# tviic2d6mddr register map
Vendor: Cypress Semiconductor; Series: tviic2d6mddr; File version: 1.0
CPU: CM7 r0p1, little endian, MPU, FPU, VTOR, 3 interrupt priority bits
Registers are 32-bit, read-write, reset 0x0 unless marked. A register's access mark holds for its fields unless they carry their own. Offsets are from the block's base; [hi:lo] are bit positions; lines under a group give offsets from that group; {n}, {i} and the like mark numbered series; 'fields as' and 'values as' point back to an identical list.

## TCPWM0 — Timer/Counter/PWM
Base 0x40380000
{0x0+0x8000*i} GRP[{i}] (i=0..2) group — Group of counters
  {0x0+0x80*j} CNT[{j}] (j=0..37) group — Timer/Counter/PWM Counter Module
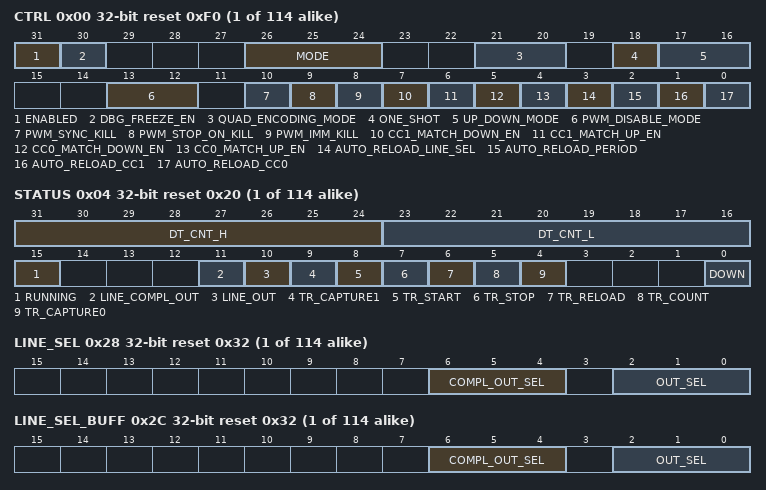
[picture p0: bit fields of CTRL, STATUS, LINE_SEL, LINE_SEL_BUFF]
    0x00 CTRL reset 0xF0 — Counter control register
      [31] ENABLED — Counter Enable '0': counter disabled. '1': counter enabled. Counter static configuration register fields should only be modified when the counter is disabled. When a counter is disabled, command and status information associated to the counter is cleared by HW, this includes: - the associated counter triggers in the CMD register are set to '0'. - the counter's interrupt cause fields in counter's INTR register. - the counter's status fields in counter's STATUS register.. - the counter's trigger outputs ('tr_out0' and tr_out1'). - the counter's line outputs ('line_out' and 'line_compl_out'). The following are Counter static configuration registers: CTRL (with the exception of DEBUG_FREEZE_EN bit), DT, TR_IN_SEL0, TR_IN_SEL1, TR_IN_EDGE_SEL, TR_PWM_CTRL_TR_OUT_SEL,INTR, INTR_MASK, INTR_MASKED Modifying these registers while the counter is running could produce unexcepted waveform results, but will not cause a fatal issue such as an illegal stop, lost control, or waveform stability issues.
      [30] DBG_FREEZE_EN — Specifies the counter behavior in debug mode. '0': The counter operation continues in debug mode. '1': The counter operation freezes in debug mode.
      [26:24] MODE — Counter mode.
        0=TIMER (Timer mode); 1=RSVD1 (N/A); 2=CAPTURE (Capture mode); 3=QUAD (Quadrature mode Different encoding modes can be selected by QUAD_ENCODING_MODE including up/down count functionality. Different counter range, reload value and capture behavior can be selected by QUAD_RANGE_MODE (overloaded field UP_DOWN_MODE).); 4=PWM (Pulse width modulation (PWM) mode); 5=PWM_DT (PWM with deadtime insertion mode); 6=PWM_PR (Pseudo random pulse width modulation); 7=SR (Shift register mode.)
      [21:20] QUAD_ENCODING_MODE — In QUAD mode this field selects the quadrature encoding mode (X1/X2/X4) or the Up / Down rotary counting mode. In PWM, PWM_DT and PWM_PR modes, these two bits can be used to invert 'dt_line_out' and 'dt_line_compl_out'. Inversion is the last step in generation of 'dt_line_out' and 'dt_line_compl_out'; i.e. a disabled output line 'dt_line_out' has the value QUAD_ENCODING_MODE[0] and a disabled output line 'dt_line_compl_out' has the value QUAD_ENCODING_MODE[1].
        0=X1 encoding (QUAD mode) This encoding is identical with an up / down counting functionality of the following way: Rising edges of input phiA increment or decrement the counter depending on the state of input phiB (direction input); 1=X2 (X2 encoding (QUAD mode)); 2=X4 (X4 encoding (QUAD mode)); 3=UP_DOWN (Up / Down rotary counting mode. Input phiA increments the counter, input phiB decrements the counter. The trigger edge detection settings apply.)
      [18] ONE_SHOT — When '0', counter runs continuous. When '1', counter is turned off by hardware when a terminal count event is generated.
      [17:16] UP_DOWN_MODE — Determines counter direction. In QUAD mode this field acts as QUAD_RANGE_MODE field selecting between different counter range, reload value and compare / capture behavior.
        0=COUNT_UP (Count up (to PERIOD). An overflow event is generated when the counter changes from a state in which COUNTER equals PERIOD. A terminal count event is generated when the counter changes from a state in which COUNTER equals PERIOD.); 1=COUNT_DOWN (Count down (to '0'). An underflow event is generated when the counter changes from a state in which COUNTER equals '0'. A terminal count event is generated when the counter changes from a state in which COUNTER equals '0'.); 2=COUNT_UPDN1 (Count up (to PERIOD), then count down (to '0'). An overflow event is generated when the counter changes from a state in which COUNTER equals PERIOD. An underflow event is generated when the counter changes from a state in which COUNTER equals '0'. A terminal count event is generated when the counter changes from a state in which COUNTER equals '0'.); 3=COUNT_UPDN2 (Count up (to PERIOD), then count down (to '0'). An overflow event is generated when the counter changes from a state in which COUNTER equals PERIOD. An underflow event is generated when the counter changes from a state in which COUNTER equals '0'. A terminal count event is generated when the counter changes from a state in which COUNTER equals '0' AND when the counter changes from a state in which COUNTER equals PERIOD (this counter direction can be used for PWM functionality with asymmetrical updates).)
      [13:12] PWM_DISABLE_MODE — Specifies the behavior of the PWM outputs 'line_out' and 'line_compl_out' while the TCPWM counter is disabled (CTL.ENABLED='0') or stopped. Note: The output signal of this selection can be further modified by the immediate kill logic and line_out polarity settings (CTRL.QUAD_ENCODING_MODE).
        0=Z (The behavior is the same is in previous mxtcpwm (version 1). When the counter is disabled the PWM outputs 'line_out' and 'line_compl_out' are NOT driven by the TCPWM. Instead the port default level configuration applies, e.g. 'Z' (high impedance). Note: This is realized by driving the TCPWM output 'line_out_en' to 0. When the counter is stopped upon a stop event the PWM outputs are deactivated (to the polarity defined by CTL.QUAD_ENCODING_MODE).); 1=RETAIN (When the counter is disabled the PWM outputs 'line_out' and 'line_compl_out' are driven by the TCPWM. When the counter is disabled or stopped upon a stop event the PWM outputs are retained (keep their previous levels). While the counter is disabled or stopped the PWM outputs can be changed via LINE_SEL (when parameter GRP_SMC_PRESENT = 1).); 2=L (When the counter is disabled the PWM outputs 'line_out' and 'line_compl_out' are driven by the TCPWM. When the counter is disabled or stopped upon a stop event the PWM output 'line_out' is driven as a fixed '0' and the PWM output 'line_compl_out' is driven as a fixed '1'.); 3=H (When the counter is disabled the PWM outputs 'line_out' and 'line_compl_out' are driven by the TCPWM. When the counter is disabled or stopped upon a stop event the PWM output 'line_out' is driven as a fixed '1' and the PWM output 'line_compl_out' is driven as a fixed '0'.)
      [10] PWM_SYNC_KILL — Specifies asynchronous/synchronous kill behavior: '1': synchronous kill mode: the kill event disables the 'dt_line_out' and 'dt_line_compl_out' signals till the next terminal count event (synchronous kill). In synchronous kill mode, STOP_EDGE should be RISING_EDGE. '0': asynchronous kill mode: the kill event only disables the 'dt_line_out' and 'dt_line_compl_out' signals when present. In asynchronous kill mode, STOP_EDGE should be NO_EDGE_DET. This field has a function in PWM and PWM_DT modes only. This field is only used when PWM_STOP_ON_KILL is '0'.
      [9] PWM_STOP_ON_KILL — Specifies whether the counter stops on a kill events: '0': kill event does NOT stop counter. '1': kill event stops counter. This field has a function in PWM, PWM_DT and PWM_PR modes only.
      [8] PWM_IMM_KILL — Specifies whether the kill event immediately deactivates the 'dt_line_out' and 'dt_line_compl_out' signals or with the next module clock ('active count' pre-scaled 'clk_counter'). '0': synchronous kill activation. Deactivates the 'dt_line_out' and 'dt_line_compl_out' signals with the next module clock ('active count' pre-scaled 'clk_counter'). '1': immediate kill activation. Immediately deactivates the 'dt_line_out' and 'dt_line_compl_out' signals. This field has a function in PWM, PWM_DT and PWM_PR modes only.
      [7] CC1_MATCH_DOWN_EN — Enables / disables the compare match 1 event generation (COUNTER equals CC0 register) when counting down (STATUS.DOWN = 1) in CNT_UPDN1/2 mode. '0': compare match 1 event generation disabled when counting down '1': compare match 1 event generation enabled when counting down This field has a function in PWM and PWM_DT modes only.
      [6] CC1_MATCH_UP_EN — Enables / disables the compare match 1 event generation (COUNTER equals CC0 register) when counting up (STATUS.DOWN = 0) in CNT_UPDN1/2 mode. '0': compare match 1 event generation disabled when counting up '1': compare match 1 event generation enabled when counting up This field has a function in PWM and PWM_DT modes only.
      [5] CC0_MATCH_DOWN_EN — Enables / disables the compare match 0 event generation (COUNTER equals CC0 register) when counting down (STATUS.DOWN = 1) in CNT_UPDN1/2 mode. '0': compare match 0 event generation disabled when counting down '1': compare match 0 event generation enabled when counting down This field has a function in PWM and PWM_DT modes only.
      [4] CC0_MATCH_UP_EN — Enables / disables the compare match 0 event generation (COUNTER equals CC0 register) when counting up (STATUS.DOWN = 0) in CNT_UPDN1/2 mode. '0': compare match 0 event generation disabled when counting up '1': compare match 0 event generation enabled when counting up This field has a function in PWM and PWM_DT modes only.
      [3] AUTO_RELOAD_LINE_SEL — Specifies switching of the LINE_SEL and LINE_BUFF_SEL values. This field has a function in PWM and PWM_PR modes. '0': never switch. '1': switch on a terminal count event with an actively pending switch event.
      [2] AUTO_RELOAD_PERIOD — Specifies switching of the PERIOD and buffered PERIOD values. This field has a function in PWM and PWM_DT modes. '0': never switch. '1': switch on a terminal count event with an actively pending switch event. In QUAD mode, QUAD_RANGE0_CMP range mode this field is used to select the index / wrap-around capture function. '0': Captures on index (reload) event. The counter value is copied to the PERIOD register on an index (reload) event. '1': Captures when COUNTER equals 0 or 0xffff. The counter value is copied to the PERIOD register when COUNTER equals 0 or 0xffff.
      [1] AUTO_RELOAD_CC1 — Specifies switching of the CC1 and buffered CC1 values. This field has a function in TIMER, QUAD (QUAD_RANGE0_CMP, QUAD_RANGE1_CMP range modes), SR, PWM, PWM_DT and PWM_PR modes. Timer, QUAD, SR modes: '0': never switch. '1': switch on a compare match 1 event. PWM, PWM_DT, PWM_PR modes: '0: never switch. '1': switch on a terminal count event with an actively pending switch event.
      [0] AUTO_RELOAD_CC0 — Specifies switching of the CC0 and buffered CC0 values. This field has a function in TIMER, QUAD (QUAD_RANGE0_CMP, QUAD_RANGE1_CMP range modes), SR, PWM, PWM_DT and PWM_PR modes. Timer, QUAD, SR modes: '0': never switch. '1': switch on a compare match 0 event. PWM, PWM_DT, PWM_PR modes: '0: never switch. '1': switch on a terminal count event with an actively pending switch event.
    0x04 STATUS ro reset 0x20 — Counter status register
      [31:24] DT_CNT_H — High byte of 16-bit dead time counter. In PWM_DT mode, this counter is used for dead time insertion. In all other modes, this field has no effect. Note: This field only exists when parameter GRP_AMC_PRESENT for advanced motor control is set to 1. Otherwise the dead time is only 8bit wide and the only the field DT_CNT_L is used as dead time counter.
      [23:16] DT_CNT_L — Generic 8-bit counter field. In PWM_DT mode, this counter is used for dead time insertion (8bit dead time counter or low byte of 16-bit dead time counter). In all other modes, this counter is used for pre-scaling the selected counter clock. PWM_DT mode can NOT use prescaled clock functionality.
      [15] RUNNING — When '0', the counter is NOT running. When '1', the counter is running. This field is used to indicate that the counter is running after a start/reload event and that the counter is stopped after a stop event. When a running counter operation is paused in debug state (see CTRL.DBG_PAUSE) then the RUNNING bit is still '1'.
      [11] LINE_COMPL_OUT — Indicates the actual level of the complementary PWM line output signal.
      [10] LINE_OUT — Indicates the actual level of the PWM line output signal.
      [9] TR_CAPTURE1 — Indicates the actual level of the selected capture 1 trigger.
      [8] TR_START — Indicates the actual level of the selected start trigger.
      [7] TR_STOP — Indicates the actual level of the selected stop trigger.
      [6] TR_RELOAD — Indicates the actual level of the selected reload trigger.
      [5] TR_COUNT — Indicates the actual level of the selected count trigger.
      [4] TR_CAPTURE0 — Indicates the actual level of the selected capture 0 trigger.
      [0] DOWN — When '0', counter is counting up. When '1', counter is counting down. In QUAD mode, this field indicates the direction of the latest counter change: '0' when last incremented and '1' when last decremented.
    0x08 COUNTER — Counter count register
      [31:0] COUNTER — 16-bit / 32-bit counter value. It is advised to not write to this field when the counter is running.
    0x10 CC0 reset 0xFFFFFFFF — Counter compare/capture 0 register
      [31:0] CC — In CAPTURE mode, captures the counter value. In other modes, compared to counter value.
    0x14 CC0_BUFF reset 0xFFFFFFFF — Counter buffered compare/capture 0 register
      [31:0] CC — Additional buffer for counter CC register.
    0x18 CC1 reset 0xFFFFFFFF — Counter compare/capture 1 register
      fields as GRP[0].CNT[0].CC0
    0x1C CC1_BUFF reset 0xFFFFFFFF — Counter buffered compare/capture 1 register
      [31:0] CC — Additional buffer for counter CC1 register.
    0x20 PERIOD reset 0xFFFFFFFF — Counter period register
      [31:0] PERIOD — Period value: upper value of the counter. When the counter should count for n cycles, this field should be set to n-1.
    0x24 PERIOD_BUFF reset 0xFFFFFFFF — Counter buffered period register
      [31:0] PERIOD — Additional buffer for counter PERIOD register. In PWM_PR mode PEROD_BUFF defines the LFSR polynomial. Each bit represents a tap of the shift register which can be feed back to the MSB via an XOR tree. Examples for GRP_CNT_WIDTH = 16: - Maximum length 16bit LFSR - polynomial x^16 + x^14 + x^13 + x^11 + 1 - taps 0,2,3,5 -> PERIOD = 0x002d - period is 2^16-1 = 65535 cycles - Maximum length 8bit LFSR: - polynomial x^8 + x^6 + x^5 + x^4 + 1 - taps 8,10,11,12 (realized in 8 MSBs of 16bit LFSR) - period is 2^8-1 = 255 cycles In SR mode PERIOD_BUFF defines which tap of the shift register generates the PWM output signals. For a delay of n cycles (from capture event to PWM output) the bit CNT_WIDTH-n should be set to '1'. For a shift register function only one tap should be use, i.e. a one-hot value must be written to PERIOD_BUFF. If multiple bits in PERIOD_BUFF are set then the taps are XOR combined.
    0x28 LINE_SEL reset 0x32 — Counter line selection register
      [6:4] COMPL_OUT_SEL — Selects the source for the output signal 'line_compl_out'. Default setting is the inverted PWM signal 'line'. Other settings are useful for Stepper Motor Control. This field has a function in PWM and PWM_PR modes only. Note: The output signal of this selection can be further modified by the stop / kill logic and line_compl_out polarity setting (CTRL.QUAD_ENCODING_MODE[1]).
        0=L (fixed '0'); 1=H (fixed '1'); 2=PWM (PWM signal 'line'); 3=PWM_INV (inverted PWM signal 'line'); 4=Z (The output 'line_compl_out' is not driven by the TCPWM. Instead the port default level configuration applies, e.g. 'Z' (high impedance). Note: This is realized by driving the output 'line_compl_out_en' to 0.); 5=RSVD5 (N/A); 6=RSVD6 (N/A); 7=RSVD7 (N/A)
      [2:0] OUT_SEL — Selects the source for the output signal 'line_out'. Default setting is the PWM signal 'line'. Other settings are useful for Stepper Motor Control. This field has a function in PWM and PWM_PR modes only. Note: The output signal of this selection can be further modified by the stop / kill logic and line_out polarity setting (CTRL.QUAD_ENCODING_MODE[0]).
        0=L (fixed '0'); 1=H (fixed '1'); 2=PWM (PWM signal 'line'); 3=PWM_INV (inverted PWM signal 'line'); 4=Z (The output 'line_out' is not driven by the TCPWM. Instead the port default level configuration applies, e.g. 'Z' (high impedance). Note: This is realized by driving the output 'line_out_en' to 0.); 5=RSVD5 (N/A); 6=RSVD6 (N/A); 7=RSVD7 (N/A)
    0x2C LINE_SEL_BUFF reset 0x32 — Counter buffered line selection register
      [6:4] COMPL_OUT_SEL — Buffer for LINE_SEL.COMPL.OUT_SEL. Can be exchanged with LINE_SEL.LINE_COMPL_OUT_SEL on a terminal count event with an actively pending switch event. This field has a function in PWM and PWM_PR modes only.
      [2:0] OUT_SEL — Buffer for LINE_SEL.OUT_SEL. Can be exchanged with LINE_SEL.LINE_OUT_SEL on a terminal count event with an actively pending switch event. This field has a function in PWM and PWM_PR modes only.
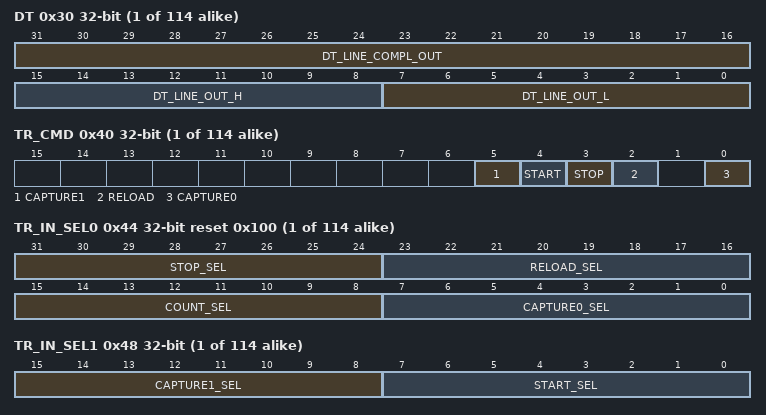
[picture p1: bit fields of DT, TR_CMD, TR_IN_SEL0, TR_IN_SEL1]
    0x30 DT — Counter PWM dead time register
      [31:16] DT_LINE_COMPL_OUT — In PWM_DT mode, this field is used to determine the dead time before activating the complementary PWM line output signal 'line_compl_out': amount of dead time cycles in the counter clock domain. In all other modes, this field has no effect. Note: This field only exists when parameter GRP_AMC_PRESENT for advanced motor control is set to 1. Otherwise the dead time is only 8 bit wide and the same dead time specified by field DT_LINE_OUT_L is used before activating 'line_out' and 'line_compl_out'.
      [15:8] DT_LINE_OUT_H — In PWM_DT mode, this field is used to determine the high byte of the dead time before activating the PWM line output signal 'line_out': amount of dead time cycles in the counter clock domain. In all other modes, this field has no effect. Note: This field only exists when parameter GRP_AMC_PRESENT for advanced motor control is set to 1. Otherwise the dead time is only 8 bit wide and the same dead time specified by field DT_LINE_OUT_L is used before activating 'line_out' and 'line_compl_out'.
      [7:0] DT_LINE_OUT_L — In PWM_DT mode, this field is used to determine the low byte of the dead time before activating the PWM line output signal 'line_out': amount of dead time cycles in the counter clock domain. In all other modes, the lower 3 bits of this field determine pre-scaling of the selected counter clock. Note: This field determines the low byte of the 16-bit dead time before activating 'line_out' when parameter GRP_AMC_PRESENT for advanced motor control is set to 1. Otherwise the dead time is only 8 bit wide and the same dead time specified by this DT_LINE_OUT_L field is used before activating 'line_out' and 'line_compl_out'.
    0x40 TR_CMD — Counter trigger command register
      [5] CAPTURE1 — SW capture 1 trigger. For HW behavior, see COUNTER_CAPTURE0 field.
      [4] START — SW start trigger. For HW behavior, see COUNTER_CAPTURE0 field.
      [3] STOP — SW stop trigger. For HW behavior, see COUNTER_CAPTURE0 field.
      [2] RELOAD — SW reload trigger. For HW behavior, see COUNTER_CAPTURE0 field.
      [0] CAPTURE0 — SW capture 0 trigger. When written with '1', a capture 0 trigger is generated and the HW sets the field to '0' when the SW trigger has taken effect. It should be noted that the HW operates on the counter frequency. If the counter is disabled through CTRL.ENABLED, the field is immediately set to '0'.
    0x44 TR_IN_SEL0 reset 0x100 — Counter input trigger selection register 0
      [31:24] STOP_SEL — Selects one of the 256 input triggers as a stop trigger. In PWM, PWM_DT and PWM_PR modes, this is the kill trigger. In these modes, the kill trigger is used to either temporarily block the PWM outputs (PWM_STOP_ON_KILL is '0') or stop the functionality (PWM_STOP_ON_KILL is '1'). For the PWM and PWM_DT modes, the blocking of the output signals can be asynchronous (STOP_EDGE should be NO_EDGE_DET) in which case the blocking is as long as the trigger is '1' or synchronous (STOP_EDGE should be RISING_EDGE) in which case it extends till the next terminal count event.
      [23:16] RELOAD_SEL — Selects one of the 256 input triggers as a reload trigger. In QUAD mode, this is the index or revolution pulse. In these modes, it will update the counter with 0x8000 (counter midpoint) or 0x0000 depending on the QUAD_RANGE_MODE.
      [15:8] COUNT_SEL — Selects one of the 256 input triggers as a count trigger. In QUAD mode, this is the first phase (phi A). Default setting selects input trigger 1, which is always '1'. Note: In the modes: TIMER, CAPTURE, PWM, PWM_DT, and SR, If the counter is externally triggered ( COUNT_SEL > 1), an external trigger will be required for each TR_CMD to execute. For example, a write to TR_CMD.START will not start the counter until the trigger selected by COUNT_SEL asserts. The next trigger will increment the counter since the counter is now running. This goes for all TR_CMD fields.
      [7:0] CAPTURE0_SEL — Selects one of the up to 256 input triggers as a capture0 trigger. Input trigger 0 is always '0' and input trigger 1 is always '1'. If existing, the one-to-one trigger inputs 'tr_one_cnt_in' (different to each counter) are selected by setting 2 and above. The settings above are used for the general purpose trigger inputs 'tr_all_cnt_in' connected to all counters selected. In the PWM, PWM_DT and PWM_PR modes this trigger is used to switch the values if the compare and period registers with their buffer counterparts.
    0x48 TR_IN_SEL1 — Counter input trigger selection register 1
      [15:8] CAPTURE1_SEL — Selects one of the 256 input triggers as a capture 1 trigger.
      [7:0] START_SEL — Selects one of the 256 input triggers as a start trigger. In QUAD mode, this is the second phase (phi B).
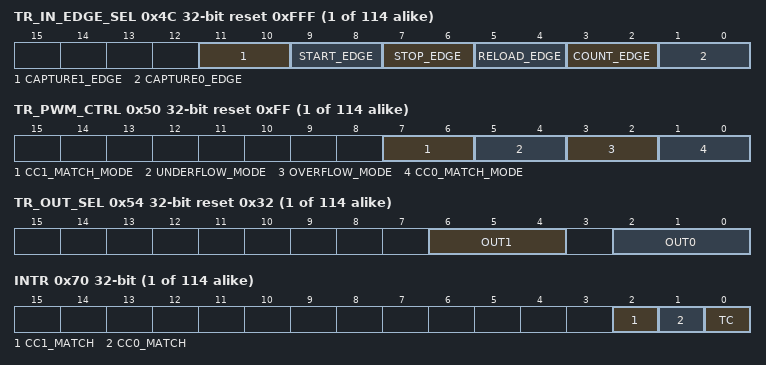
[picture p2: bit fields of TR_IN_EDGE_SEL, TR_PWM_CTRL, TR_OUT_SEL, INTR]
    0x4C TR_IN_EDGE_SEL reset 0xFFF — Counter input trigger edge selection register
      [all] fields
        0=RISING_EDGE (Rising edge. Any rising edge generates an event.); 1=FALLING_EDGE (Falling edge. Any falling edge generates an event.); 2=ANY_EDGE (Rising AND falling edge. Any odd amount of edges generates an event.); 3=NO_EDGE_DET (No edge detection, use trigger as is.)
      [11:10] CAPTURE1_EDGE — A capture 1 event will copy the counter value into the CC1 register.
      [9:8] START_EDGE — A start event will start the counter; i.e. the counter will become running. Starting does NOT enable the counter. A start event will not initialize the counter whereas the reload event does.
      [7:6] STOP_EDGE — A stop event, will stop the counter; i.e. it will no longer be running. Stopping will NOT disable the counter.
      [5:4] RELOAD_EDGE — A reload event will initialize the counter. When counting up, the counter is initialized to '0'. When counting down, the counter is initialized with PERIOD.
      [3:2] COUNT_EDGE — A counter event will increase or decrease the counter by '1'.
      [1:0] CAPTURE0_EDGE — A capture 0 event will copy the counter value into the CC0 register.
    0x50 TR_PWM_CTRL reset 0xFF — Counter trigger PWM control register
      [all] fields
        0=SET (Set to '1'); 1=CLEAR (Set to '0'); 2=INVERT; 3=NO_CHANGE
      [7:6] CC1_MATCH_MODE — Determines the effect of a compare match 1 event (COUNTER equals CC1 register) on the 'line_out' output signals.
      [5:4] UNDERFLOW_MODE — Determines the effect of a counter underflow event (COUNTER reaches '0') on the 'line_out' output signals.
      [3:2] OVERFLOW_MODE — Determines the effect of a counter overflow event (COUNTER reaches PERIOD) on the 'line_out' output signals.
      [1:0] CC0_MATCH_MODE — Determines the effect of a compare match 0 event (COUNTER equals CC0 register) on the 'line_out' output signals. Note that INVERT is especially useful for center aligned pulse width modulation. To generate a duty cycle of 0 percent, the counter CC0 register should be set to '0'. For a 100 percent duty cycle, the counter CC0 register should be set to larger than the counter PERIOD register.
    0x54 TR_OUT_SEL reset 0x32 — Counter output trigger selection register
      [6:4] OUT1 — Selects one of the internal events to generate the output trigger 1. Default setting selects the compare match 0 event.
        0=OVERFLOW (Overflow event); 1=UNDERFLOW (Underflow event); 2=TC (Terminal count event); 3=CC0_MATCH (Compare match 0 event (default selection)); 4=CC1_MATCH (Compare match 1 event); 5=LINE_OUT (PWM output signal 'line_out'); 6=RSVD6 (N/A); 7=Disabled (Output trigger disabled.)
      [2:0] OUT0 — Selects one of the internal events to generate the output trigger 0. Default setting selects the terminal count event.
        0=OVERFLOW (Overflow event); 1=UNDERFLOW (Underflow event); 2=TC (Terminal count event (default selection)); 3=CC0_MATCH (Compare match 0 event); 4=CC1_MATCH (Compare match 1 event); 5=LINE_OUT (PWM output signal 'line_out'); 6=RSVD6 (N/A); 7=Disabled (Output trigger disabled.)
    0x70 INTR — Interrupt request register
      [2] CC1_MATCH — Counter matches CC1 register event. Set to '1', when event is detected. Write with '1' to clear bit.
      [1] CC0_MATCH — Counter matches CC0 register event. Set to '1', when event is detected. Write with '1' to clear bit.
      [0] TC — Terminal count event. Set to '1', when event is detected. Write with '1' to clear bit.
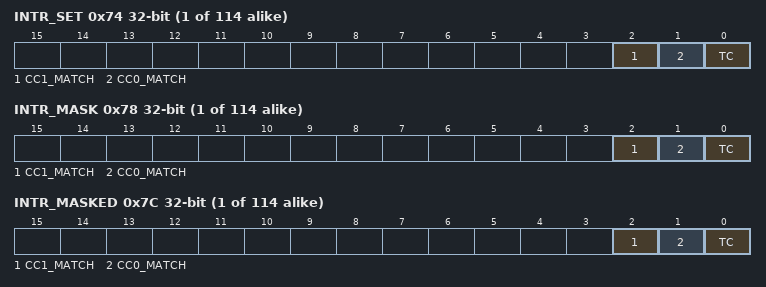
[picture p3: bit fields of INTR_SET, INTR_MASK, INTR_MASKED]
    0x74 INTR_SET — Interrupt set request register
      [2] CC1_MATCH — Write with '1' to set corresponding bit in interrupt request register.
      [1] CC0_MATCH — Write with '1' to set corresponding bit in interrupt request register.
      [0] TC — Write with '1' to set corresponding bit in interrupt request register.
    0x78 INTR_MASK — Interrupt mask register
      [2] CC1_MATCH — Mask bit for corresponding bit in interrupt request register.
      [1] CC0_MATCH — Mask bit for corresponding bit in interrupt request register.
      [0] TC — Mask bit for corresponding bit in interrupt request register.
    0x7C INTR_MASKED ro — Interrupt masked request register
      [2] CC1_MATCH — Logical and of corresponding request and mask bits.
      [1] CC0_MATCH — Logical and of corresponding request and mask bits.
      [0] TC — Logical and of corresponding request and mask bits.
